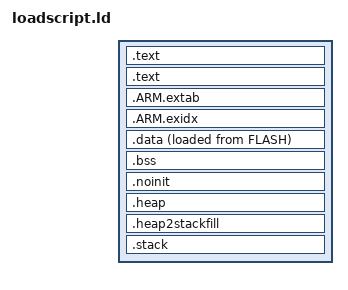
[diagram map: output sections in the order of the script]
/*
 * (C) Copyright 2020
 * Zimplistic Private Limited
 * Sicris Rey Embay, sicris@zimplistic.com
 */
 
 INCLUDE "libs.ld"
 INCLUDE "mem.ld"
 
 ENTRY(Reset_Handler)
 
 SECTIONS
 {
    .text : ALIGN(4)
    {
        FILL(0xff)
        __vectors_start__ = ABSOLUTE(.) ;
        KEEP(*(.isr_vector))
        __vectors_end__ = .;
        
        /* Global Section Table */
        . = ALIGN(4) ;
        __section_table_start = .;
        __data_section_table = .;
        LONG((LOADADDR(.data)));
        LONG(     ADDR(.data));
        LONG(   SIZEOF(.data));
        __data_section_table_end = .;
        __bss_section_table = .;
        LONG(    ADDR(.bss));
        LONG(  SIZEOF(.bss));
        __bss_section_table_end = .;
        __section_table_end = . ;
        /* End of Global Section Table */

        *(.after_vectors.reset)
        *(.after_vectors*)

    } > FLASH
    
    .text : ALIGN(4)
    {
       *(.text*)
       *(.rodata .rodata.* .constdata .constdata.*)
       . = ALIGN(4);
    } > FLASH
    
    /*
     * for exception handling/unwind - some Newlib functions (in common
     * with C++ and STDC++) use this. 
     */
    .ARM.extab : ALIGN(4) 
    {
        *(.ARM.extab* .gnu.linkonce.armextab.*)
    } > FLASH

    __exidx_start = .;

    .ARM.exidx : ALIGN(4)
    {
        *(.ARM.exidx* .gnu.linkonce.armexidx.*)
    } > FLASH
    __exidx_end = .;

    _etext = .;
    
    .data : ALIGN(4)
    {
       FILL(0xff)
       _data = . ;
       *(.data*)
       . = ALIGN(4) ;
       _edata = . ;
    } > RAM AT>FLASH
    
    .bss : ALIGN(4)
    {
        _bss = .;
        *(.bss*)
        *(COMMON)
        . = ALIGN(4) ;
        _ebss = .;
        PROVIDE(end = .);    
    } > RAM
    
    .noinit (NOLOAD) : ALIGN(4)
    {
        _noinit = .;
        *(.noinit*) 
         . = ALIGN(4) ;
        _end_noinit = .;
    } > RAM
    
    /* Reserve and place Heap within memory map */
    .heap :  ALIGN(4)
    {
        _pvHeapStart = .;
        . += _HeapSize;
        . = ALIGN(4);
        _pvHeapLimit = .;
    } > RAM
    
    /* Reserve space in memory for Stack */
    .heap2stackfill  :
    {
        . += _StackSize;
    } > RAM
    /* Locate actual Stack in memory map */
    .stack ORIGIN(RAM) + LENGTH(RAM) - _StackSize - 0:  ALIGN(4)
    {
        _vStackBase = .;
        . = ALIGN(4);
        _vStackTop = . + _StackSize;
    } > RAM

    /* Provide basic symbols giving location and size of main text
     * block, including initial values of RW data sections. Note that
     * these will need extending to give a complete picture with
     * complex images (e.g multiple Flash banks).
     */
    _image_start = LOADADDR(.text);
    _image_end = LOADADDR(.data) + SIZEOF(.data);
    _image_size = _image_end - _image_start;
}
